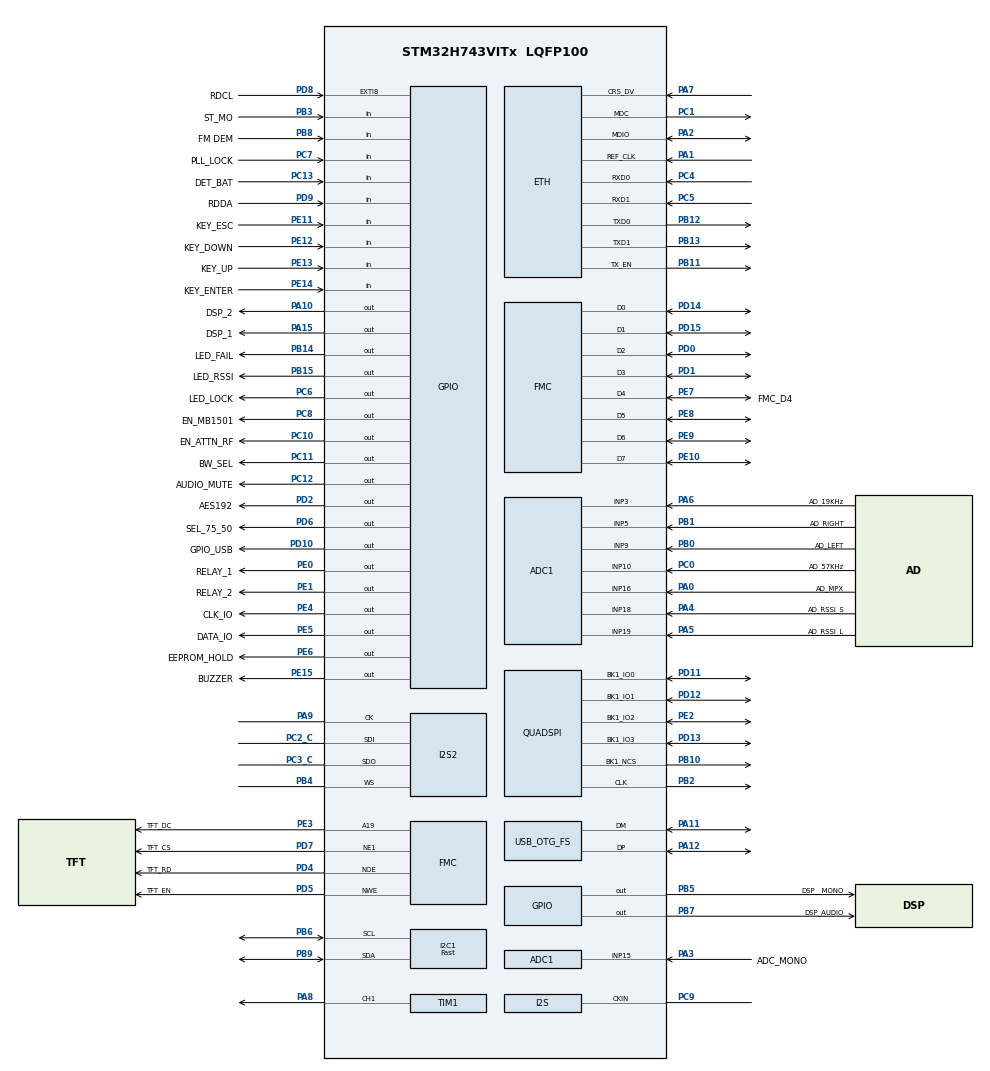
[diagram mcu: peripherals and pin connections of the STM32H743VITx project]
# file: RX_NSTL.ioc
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ADC1.Channel-0\#ChannelRegularConversion=ADC_CHANNEL_16
ADC1.Channel-1\#ChannelRegularConversion=ADC_CHANNEL_15
ADC1.Channel-2\#ChannelRegularConversion=ADC_CHANNEL_18
ADC1.Channel-3\#ChannelRegularConversion=ADC_CHANNEL_19
ADC1.Channel-5\#ChannelRegularConversion=ADC_CHANNEL_3
ADC1.Channel-6\#ChannelRegularConversion=ADC_CHANNEL_9
ADC1.Channel-7\#ChannelRegularConversion=ADC_CHANNEL_5
ADC1.Channel-8\#ChannelRegularConversion=ADC_CHANNEL_10
ADC1.ClockPrescaler=ADC_CLOCK_ASYNC_DIV4
ADC1.ContinuousConvMode=ENABLE
ADC1.ConversionDataManagement=ADC_CONVERSIONDATA_DMA_CIRCULAR
ADC1.NbrOfConversion=8
ADC1.NbrOfConversionFlag=1
ADC1.OffsetNumber-0\#ChannelRegularConversion=ADC_OFFSET_NONE
ADC1.OffsetNumber-1\#ChannelRegularConversion=ADC_OFFSET_NONE
ADC1.OffsetNumber-2\#ChannelRegularConversion=ADC_OFFSET_NONE
ADC1.OffsetNumber-3\#ChannelRegularConversion=ADC_OFFSET_NONE
ADC1.OffsetNumber-5\#ChannelRegularConversion=ADC_OFFSET_NONE
ADC1.OffsetNumber-6\#ChannelRegularConversion=ADC_OFFSET_NONE
ADC1.OffsetNumber-7\#ChannelRegularConversion=ADC_OFFSET_NONE
ADC1.OffsetNumber-8\#ChannelRegularConversion=ADC_OFFSET_NONE
ADC1.OffsetSignedSaturation-0\#ChannelRegularConversion=DISABLE
ADC1.OffsetSignedSaturation-1\#ChannelRegularConversion=DISABLE
ADC1.OffsetSignedSaturation-2\#ChannelRegularConversion=DISABLE
ADC1.OffsetSignedSaturation-3\#ChannelRegularConversion=DISABLE
ADC1.OffsetSignedSaturation-5\#ChannelRegularConversion=DISABLE
ADC1.OffsetSignedSaturation-6\#ChannelRegularConversion=DISABLE
ADC1.OffsetSignedSaturation-7\#ChannelRegularConversion=DISABLE
ADC1.OffsetSignedSaturation-8\#ChannelRegularConversion=DISABLE
ADC1.Overrun=ADC_OVR_DATA_OVERWRITTEN
ADC1.Rank-0\#ChannelRegularConversion=1
ADC1.Rank-1\#ChannelRegularConversion=2
ADC1.Rank-2\#ChannelRegularConversion=3
ADC1.Rank-3\#ChannelRegularConversion=4
ADC1.Rank-5\#ChannelRegularConversion=5
ADC1.Rank-6\#ChannelRegularConversion=6
ADC1.Rank-7\#ChannelRegularConversion=7
ADC1.Rank-8\#ChannelRegularConversion=8
ADC1.SamplingTime-0\#ChannelRegularConversion=ADC_SAMPLETIME_810CYCLES_5
ADC1.SamplingTime-1\#ChannelRegularConversion=ADC_SAMPLETIME_810CYCLES_5
ADC1.SamplingTime-2\#ChannelRegularConversion=ADC_SAMPLETIME_810CYCLES_5
ADC1.SamplingTime-3\#ChannelRegularConversion=ADC_SAMPLETIME_810CYCLES_5
ADC1.SamplingTime-5\#ChannelRegularConversion=ADC_SAMPLETIME_810CYCLES_5
ADC1.SamplingTime-6\#ChannelRegularConversion=ADC_SAMPLETIME_810CYCLES_5
ADC1.SamplingTime-7\#ChannelRegularConversion=ADC_SAMPLETIME_810CYCLES_5
ADC1.SamplingTime-8\#ChannelRegularConversion=ADC_SAMPLETIME_810CYCLES_5
ADC1.master=1
ADC3.Channel-0\#ChannelRegularConversion=ADC_CHANNEL_TEMPSENSOR
ADC3.Channel-1\#ChannelRegularConversion=ADC_CHANNEL_VBAT
ADC3.ClockPrescaler=ADC_CLOCK_ASYNC_DIV4
ADC3.ContinuousConvMode=ENABLE
ADC3.ConversionDataManagement=ADC_CONVERSIONDATA_DMA_CIRCULAR
ADC3.NbrOfConversion=2
ADC3.NbrOfConversionFlag=1
ADC3.OffsetNumber-0\#ChannelRegularConversion=ADC_OFFSET_NONE
ADC3.OffsetNumber-1\#ChannelRegularConversion=ADC_OFFSET_NONE
ADC3.OffsetSignedSaturation-0\#ChannelRegularConversion=DISABLE
ADC3.OffsetSignedSaturation-1\#ChannelRegularConversion=DISABLE
ADC3.Overrun=ADC_OVR_DATA_OVERWRITTEN
ADC3.Rank-0\#ChannelRegularConversion=1
ADC3.Rank-1\#ChannelRegularConversion=2
ADC3.SamplingTime-0\#ChannelRegularConversion=ADC_SAMPLETIME_387CYCLES_5
ADC3.SamplingTime-1\#ChannelRegularConversion=ADC_SAMPLETIME_387CYCLES_5
Bdma.ADC3.0.Direction=DMA_PERIPH_TO_MEMORY
Bdma.ADC3.0.EventEnable=DISABLE
Bdma.ADC3.0.Instance=BDMA_Channel0
Bdma.ADC3.0.MemDataAlignment=DMA_MDATAALIGN_HALFWORD
Bdma.ADC3.0.MemInc=DMA_MINC_ENABLE
Bdma.ADC3.0.Mode=DMA_CIRCULAR
Bdma.ADC3.0.PeriphDataAlignment=DMA_PDATAALIGN_HALFWORD
Bdma.ADC3.0.PeriphInc=DMA_PINC_DISABLE
Bdma.ADC3.0.Polarity=HAL_DMAMUX_REQ_GEN_RISING
Bdma.ADC3.0.Priority=DMA_PRIORITY_LOW
Bdma.ADC3.0.RequestNumber=1
Bdma.ADC3.0.SignalID=NONE
Bdma.ADC3.0.SyncEnable=DISABLE
Bdma.ADC3.0.SyncPolarity=HAL_DMAMUX_SYNC_NO_EVENT
Bdma.ADC3.0.SyncRequestNumber=1
Bdma.ADC3.0.SyncSignalID=NONE
Bdma.Request0=ADC3
Bdma.RequestsNb=1
CORTEX_M7.AccessPermission-Cortex_Memory_Protection_Unit_Region0_Settings=MPU_REGION_FULL_ACCESS
CORTEX_M7.AccessPermission-Cortex_Memory_Protection_Unit_Region1_Settings=MPU_REGION_FULL_ACCESS
CORTEX_M7.AccessPermission-Cortex_Memory_Protection_Unit_Region2_Settings=MPU_REGION_FULL_ACCESS
CORTEX_M7.AccessPermission-Cortex_Memory_Protection_Unit_Region3_Settings=MPU_REGION_FULL_ACCESS
CORTEX_M7.AccessPermission_S-Cortex_Memory_Protection_Unit_Region1_Settings_S=MPU_REGION_FULL_ACCESS
CORTEX_M7.AccessPermission_S-Cortex_Memory_Protection_Unit_Region2_Settings_S=MPU_REGION_FULL_ACCESS
CORTEX_M7.AccessPermission_S-Cortex_Memory_Protection_Unit_Region3_Settings_S=MPU_REGION_FULL_ACCESS
CORTEX_M7.AccessPermission_S-Cortex_Memory_Protection_Unit_Region4_Settings_S=MPU_REGION_FULL_ACCESS
CORTEX_M7.BaseAddress-Cortex_Memory_Protection_Unit_Region0_Settings=0x30040000
CORTEX_M7.BaseAddress-Cortex_Memory_Protection_Unit_Region1_Settings=0x30040000
CORTEX_M7.BaseAddress-Cortex_Memory_Protection_Unit_Region2_Settings=0x60000000
CORTEX_M7.BaseAddress-Cortex_Memory_Protection_Unit_Region3_Settings=0x60010000
CORTEX_M7.BaseAddress_S-Cortex_Memory_Protection_Unit_Region1_Settings_S=0x30020000
CORTEX_M7.BaseAddress_S-Cortex_Memory_Protection_Unit_Region2_Settings_S=0x30040000
CORTEX_M7.BaseAddress_S-Cortex_Memory_Protection_Unit_Region3_Settings_S=0x60000000
CORTEX_M7.BaseAddress_S-Cortex_Memory_Protection_Unit_Region4_Settings_S=0x60080000
CORTEX_M7.CPU_DCache=Enabled
CORTEX_M7.CPU_ICache=Enabled
CORTEX_M7.DisableExec-Cortex_Memory_Protection_Unit_Region0_Settings=MPU_INSTRUCTION_ACCESS_DISABLE
CORTEX_M7.DisableExec-Cortex_Memory_Protection_Unit_Region1_Settings=MPU_INSTRUCTION_ACCESS_DISABLE
CORTEX_M7.DisableExec-Cortex_Memory_Protection_Unit_Region2_Settings=MPU_INSTRUCTION_ACCESS_DISABLE
CORTEX_M7.DisableExec-Cortex_Memory_Protection_Unit_Region3_Settings=MPU_INSTRUCTION_ACCESS_DISABLE
CORTEX_M7.DisableExec_S-Cortex_Memory_Protection_Unit_Region1_Settings_S=MPU_INSTRUCTION_ACCESS_DISABLE
CORTEX_M7.DisableExec_S-Cortex_Memory_Protection_Unit_Region2_Settings_S=MPU_INSTRUCTION_ACCESS_DISABLE
CORTEX_M7.DisableExec_S-Cortex_Memory_Protection_Unit_Region3_Settings_S=MPU_INSTRUCTION_ACCESS_DISABLE
CORTEX_M7.DisableExec_S-Cortex_Memory_Protection_Unit_Region4_Settings_S=MPU_INSTRUCTION_ACCESS_DISABLE
CORTEX_M7.Enable-Cortex_Memory_Protection_Unit_Region0_Settings=MPU_REGION_ENABLE
CORTEX_M7.Enable-Cortex_Memory_Protection_Unit_Region1_Settings=MPU_REGION_ENABLE
CORTEX_M7.Enable-Cortex_Memory_Protection_Unit_Region2_Settings=MPU_REGION_ENABLE
CORTEX_M7.Enable-Cortex_Memory_Protection_Unit_Region3_Settings=MPU_REGION_ENABLE
CORTEX_M7.Enable_S-Cortex_Memory_Protection_Unit_Region1_Settings_S=MPU_REGION_ENABLE
CORTEX_M7.Enable_S-Cortex_Memory_Protection_Unit_Region2_Settings_S=MPU_REGION_ENABLE
CORTEX_M7.Enable_S-Cortex_Memory_Protection_Unit_Region3_Settings_S=MPU_REGION_ENABLE
CORTEX_M7.Enable_S-Cortex_Memory_Protection_Unit_Region4_Settings_S=MPU_REGION_ENABLE
CORTEX_M7.IsBufferable-Cortex_Memory_Protection_Unit_Region1_Settings=MPU_ACCESS_BUFFERABLE
CORTEX_M7.IsBufferable_S-Cortex_Memory_Protection_Unit_Region2_Settings_S=MPU_ACCESS_BUFFERABLE
CORTEX_M7.IsBufferable_S-Cortex_Memory_Protection_Unit_Region3_Settings_S=MPU_ACCESS_NOT_BUFFERABLE
CORTEX_M7.IsBufferable_S-Cortex_Memory_Protection_Unit_Region4_Settings_S=MPU_ACCESS_NOT_BUFFERABLE
CORTEX_M7.IsShareable-Cortex_Memory_Protection_Unit_Region1_Settings=MPU_ACCESS_SHAREABLE
CORTEX_M7.IsShareable_S-Cortex_Memory_Protection_Unit_Region2_Settings_S=MPU_ACCESS_SHAREABLE
CORTEX_M7.IsShareable_S-Cortex_Memory_Protection_Unit_Region3_Settings_S=MPU_ACCESS_NOT_SHAREABLE
CORTEX_M7.IsShareable_S-Cortex_Memory_Protection_Unit_Region4_Settings_S=MPU_ACCESS_NOT_SHAREABLE
CORTEX_M7.MPU_Control=MPU_PRIVILEGED_DEFAULT
CORTEX_M7.Size-Cortex_Memory_Protection_Unit_Region0_Settings=MPU_REGION_SIZE_32KB
CORTEX_M7.Size-Cortex_Memory_Protection_Unit_Region1_Settings=MPU_REGION_SIZE_256B
CORTEX_M7.Size-Cortex_Memory_Protection_Unit_Region2_Settings=MPU_REGION_SIZE_4KB
CORTEX_M7.Size-Cortex_Memory_Protection_Unit_Region3_Settings=MPU_REGION_SIZE_4KB
CORTEX_M7.Size_S-Cortex_Memory_Protection_Unit_Region1_Settings_S=MPU_REGION_SIZE_128KB
CORTEX_M7.Size_S-Cortex_Memory_Protection_Unit_Region2_Settings_S=MPU_REGION_SIZE_512B
CORTEX_M7.Size_S-Cortex_Memory_Protection_Unit_Region3_Settings_S=MPU_REGION_SIZE_4KB
CORTEX_M7.Size_S-Cortex_Memory_Protection_Unit_Region4_Settings_S=MPU_REGION_SIZE_4KB
CORTEX_M7.TypeExtField-Cortex_Memory_Protection_Unit_Region0_Settings=MPU_TEX_LEVEL1
CORTEX_M7.TypeExtField_S-Cortex_Memory_Protection_Unit_Region1_Settings_S=MPU_TEX_LEVEL1
CORTEX_M7.default_mode_Activation=1
DMA2D.Mode=DMA2D_M2M_PFC
Dma.ADC1.0.Direction=DMA_PERIPH_TO_MEMORY
Dma.ADC1.0.EventEnable=DISABLE
Dma.ADC1.0.FIFOMode=DMA_FIFOMODE_DISABLE
Dma.ADC1.0.Instance=DMA1_Stream0
Dma.ADC1.0.MemDataAlignment=DMA_MDATAALIGN_HALFWORD
Dma.ADC1.0.MemInc=DMA_MINC_ENABLE
Dma.ADC1.0.Mode=DMA_CIRCULAR
Dma.ADC1.0.PeriphDataAlignment=DMA_PDATAALIGN_HALFWORD
Dma.ADC1.0.PeriphInc=DMA_PINC_DISABLE
Dma.ADC1.0.Polarity=HAL_DMAMUX_REQ_GEN_RISING
Dma.ADC1.0.Priority=DMA_PRIORITY_HIGH
Dma.ADC1.0.RequestNumber=1
Dma.ADC1.0.SignalID=NONE
Dma.ADC1.0.SyncEnable=DISABLE
Dma.ADC1.0.SyncPolarity=HAL_DMAMUX_SYNC_NO_EVENT
Dma.ADC1.0.SyncRequestNumber=1
Dma.ADC1.0.SyncSignalID=NONE
Dma.MEMTOMEM.1.Direction=DMA_MEMORY_TO_MEMORY
Dma.MEMTOMEM.1.EventEnable=DISABLE
Dma.MEMTOMEM.1.FIFOMode=DMA_FIFOMODE_ENABLE
Dma.MEMTOMEM.1.FIFOThreshold=DMA_FIFO_THRESHOLD_FULL
Dma.MEMTOMEM.1.Instance=DMA1_Stream1
Dma.MEMTOMEM.1.MemBurst=DMA_MBURST_SINGLE
Dma.MEMTOMEM.1.MemDataAlignment=DMA_MDATAALIGN_BYTE
Dma.MEMTOMEM.1.MemInc=DMA_MINC_DISABLE
Dma.MEMTOMEM.1.Mode=DMA_NORMAL
Dma.MEMTOMEM.1.PeriphBurst=DMA_PBURST_SINGLE
Dma.MEMTOMEM.1.PeriphDataAlignment=DMA_PDATAALIGN_BYTE
Dma.MEMTOMEM.1.PeriphInc=DMA_PINC_ENABLE
Dma.MEMTOMEM.1.Polarity=HAL_DMAMUX_REQ_GEN_RISING
Dma.MEMTOMEM.1.Priority=DMA_PRIORITY_LOW
Dma.MEMTOMEM.1.RequestNumber=1
Dma.MEMTOMEM.1.SignalID=NONE
Dma.MEMTOMEM.1.SyncEnable=DISABLE
Dma.MEMTOMEM.1.SyncPolarity=HAL_DMAMUX_SYNC_NO_EVENT
Dma.MEMTOMEM.1.SyncRequestNumber=1
Dma.MEMTOMEM.1.SyncSignalID=NONE
Dma.Request0=ADC1
Dma.Request1=MEMTOMEM
ETH.MACAddr=00\:80\:E1\:00\:00\:02
ETH.MediaInterface=HAL_ETH_RMII_MODE
FATFS._FS_EXFAT=1
FATFS._MAX_SS=4096
FATFS._USE_LFN=2
FMC.AddressSetupTime1=8
FMC.BusTurnAroundDuration1=8
FMC.DataSetupTime1=30
FREERTOS.BinarySemaphores01=BinarySemI2C,Dynamic,NULL,;BinarySemLVGL,Dynamic,NULL,;BinarySemHTTPD,Dynamic,NULL,;BinarySemMQTT,Dynamic,NULL,Available
FREERTOS.Mutexes01=MutexI2C,Dynamic,NULL;MutexLVGL,Dynamic,NULL;MutexHTTPD,Dynamic,NULL
FREERTOS.Queues01=QueueUSART3,16,uint8_t,0,Dynamic,NULL,NULL;QueueUSART6,16,uint8_t,0,Dynamic,NULL,NULL;QueueBuzzer,1,uint32_t,0,Dynamic,NULL,NULL;QueueHttp,1,uint32_t,0,Dynamic,NULL,NULL;QueueMqtt,50,10,1,Dynamic,NULL,NULL
FREERTOS.Tasks01=TaskMain,24,1024,StartTaskMain,Default,NULL,Dynamic,NULL,NULL;TaskGUI,8,4096,StartTaskGUI,Default,NULL,Dynamic,NULL,NULL;TaskNTP,8,1024,StartTaskNTP,Default,NULL,Dynamic,NULL,NULL
FREERTOS.configCHECK_FOR_STACK_OVERFLOW=2
FREERTOS.configENABLE_FPU=0
FREERTOS.configGENERATE_RUN_TIME_STATS=1
FREERTOS.configMINIMAL_STACK_SIZE=512
FREERTOS.configRECORD_STACK_HIGH_ADDRESS=1
FREERTOS.configTOTAL_HEAP_SIZE=73728
FREERTOS.configUSE_NEWLIB_REENTRANT=1
FREERTOS.configUSE_STATS_FORMATTING_FUNCTIONS=1
I2C1.I2C_Speed_Mode=I2C_Fast
I2C1.Timing=0x00B03FDB
I2S2.AudioFreq=I2S_AUDIOFREQ_192K
I2S2.DataFormat=I2S_DATAFORMAT_24B
I2S2.ErrorAudioFreq=0.0 %
I2S2.Instance=SPI$Index
I2S2.RealAudioFreq=192.0 KHz
IWDG1.Prescaler=IWDG_PRESCALER_256
IWDG1.Reload=2500
IWDG1.Window=2500
LWIP.BSP.number=1
LWIP.CMSIS_VERSION-Enabled=1
LWIP.DEFAULT_THREAD_STACKSIZE=4096
LWIP.ETHARP_SUPPORT_VLAN=1
LWIP.GATEWAY_ADDRESS=010.055.001.001
LWIP.HTTPD_USE_CUSTOM_FSDATA=1
LWIP.IP_ADDRESS=010.055.001.011
LWIP.LINK_STATS=1
LWIP.LWIP_ALTCP=1
LWIP.LWIP_ALTCP_TLS=1
LWIP.LWIP_BROADCAST_PING=1
LWIP.LWIP_DHCP=0
LWIP.LWIP_DNS=1
LWIP.LWIP_HTTPD=1
LWIP.LWIP_HTTPD_CGI=1
LWIP.LWIP_HTTPD_DYNAMIC_HEADERS=1
LWIP.LWIP_HTTPD_FS_ASYNC_READ=1
LWIP.LWIP_HTTPD_MAX_REQ_LENGTH=2048
LWIP.LWIP_HTTPD_MAX_TAG_NAME_LEN=16
LWIP.LWIP_HTTPD_REQ_BUFSIZE=2048
LWIP.LWIP_HTTPD_SSI=1
LWIP.LWIP_HTTPD_SUPPORT_POST=1
LWIP.LWIP_MULTICAST_PING=1
LWIP.LWIP_NETCONN_FULLDUPLEX=1
LWIP.LWIP_NETIF_STATUS_CALLBACK=1
LWIP.LWIP_RAM_HEAP_POINTER=0x30020000
LWIP.LWIP_SNMP=1
LWIP.LWIP_SNTP=1
LWIP.LWIP_SO_RCVBUF=1
LWIP.LWIP_SO_RCVTIMEO=1
LWIP.LWIP_TCPIP_TIMEOUT=1
LWIP.LWIP_TCP_KEEPALIVE=1
LWIP.MEMP_NUM_FRAG_PBUF=15
LWIP.MEMP_NUM_NETBUF=10
LWIP.MEMP_NUM_NETCONN=10
LWIP.MEMP_NUM_REASSDATA=5
LWIP.MEMP_NUM_TCP_PCB=10
LWIP.MEMP_NUM_TCP_PCB_LISTEN=10
LWIP.MEMP_NUM_TCP_SEG=32
LWIP.MEM_SIZE=131048
LWIP.NETMASK_ADDRESS=255.255.255.000
LWIP.SLIPIF_THREAD_STACKSIZE=3072
LWIP.SNMP_USE_NETCONN=1
LWIP.SNMP_USE_RAW=0
LWIP.TCPIP_THREAD_PRIO=40
LWIP.TCPIP_THREAD_STACKSIZE=3072
LWIP.TCP_DEFAULT_LISTEN_BACKLOG=4
LWIP.TCP_MSS=1460
LWIP.TCP_SND_BUF=5840
LWIP.TCP_SND_QUEUELEN=16
LWIP.TCP_WND=5840
LWIP.Version=v2.1.2_Cube
LWIP0.BSP.STBoard=false
LWIP0.BSP.api=BSP_COMPONENT_DRIVER
LWIP0.BSP.component=LAN8742
LWIP0.BSP.instance=LAN8742
LWIP0.BSP.name=Driver_PHY
LWIP0.BSP.semaphore=S_LAN8742
LWIP0.BSP.solution=LAN8742
Mcu.Family=STM32H7
Mcu.Name=STM32H743VITx
Mcu.Package=LQFP100
Mdma.MDMA_Channel0.DMA1_Stream1_TC.0.BlockCount=0
Mdma.MDMA_Channel0.DMA1_Stream1_TC.0.BlockDataLength=0
Mdma.MDMA_Channel0.DMA1_Stream1_TC.0.BufferTransferLength=1
Mdma.MDMA_Channel0.DMA1_Stream1_TC.0.CircularMode=MDMA_LINEAR_LIST
Mdma.MDMA_Channel0.DMA1_Stream1_TC.0.DataAlignment=MDMA_DATAALIGN_PACKENABLE
Mdma.MDMA_Channel0.DMA1_Stream1_TC.0.DestBlockAddressOffset=0
Mdma.MDMA_Channel0.DMA1_Stream1_TC.0.DestBurst=MDMA_DEST_BURST_SINGLE
Mdma.MDMA_Channel0.DMA1_Stream1_TC.0.DestDataSize=MDMA_DEST_DATASIZE_BYTE
Mdma.MDMA_Channel0.DMA1_Stream1_TC.0.DestinationInc=MDMA_DEST_INC_DISABLE
Mdma.MDMA_Channel0.DMA1_Stream1_TC.0.DstAddress=0
Mdma.MDMA_Channel0.DMA1_Stream1_TC.0.Endianness=MDMA_LITTLE_ENDIANNESS_PRESERVE
Mdma.MDMA_Channel0.DMA1_Stream1_TC.0.Instance=MDMA_Channel0
Mdma.MDMA_Channel0.DMA1_Stream1_TC.0.MaskAddress=0
Mdma.MDMA_Channel0.DMA1_Stream1_TC.0.MaskData=0
Mdma.MDMA_Channel0.DMA1_Stream1_TC.0.Priority=MDMA_PRIORITY_MEDIUM
Mdma.MDMA_Channel0.DMA1_Stream1_TC.0.Rank=First
Mdma.MDMA_Channel0.DMA1_Stream1_TC.0.SourceBlockAddressOffset=0
Mdma.MDMA_Channel0.DMA1_Stream1_TC.0.SourceBurst=MDMA_SOURCE_BURST_SINGLE
Mdma.MDMA_Channel0.DMA1_Stream1_TC.0.SourceDataSize=MDMA_SRC_DATASIZE_BYTE
Mdma.MDMA_Channel0.DMA1_Stream1_TC.0.SourceInc=MDMA_SRC_INC_BYTE
Mdma.MDMA_Channel0.DMA1_Stream1_TC.0.SrcAddress=0
Mdma.MDMA_Channel0.DMA1_Stream1_TC.0.TransferTriggerMode=MDMA_BUFFER_TRANSFER
Mdma.MDMA_Channel0.Request0=DMA1_Stream1_TC
Mdma.MDMA_Channel0.RequestsNb=1
Mdma.RequestSet0=MDMA_Channel0
Mdma.RequestSetsNb=1
NVIC.BDMA_Channel0_IRQn=true\:5\:0\:false\:false\:true\:true\:false\:true\:true
NVIC.DMA1_Stream0_IRQn=true\:5\:0\:false\:false\:true\:true\:false\:true\:true
NVIC.DMA1_Stream1_IRQn=true\:5\:0\:true\:false\:true\:false\:true\:true\:true
NVIC.DMA2D_IRQn=true\:5\:0\:false\:false\:true\:true\:true\:true\:true
NVIC.ETH_IRQn=true\:5\:0\:false\:false\:true\:true\:true\:true\:true
NVIC.MDMA_IRQn=true\:5\:0\:false\:false\:true\:true\:false\:true\:true
NVIC.OTG_FS_IRQn=true\:5\:0\:false\:false\:true\:true\:false\:true\:true
NVIC.PriorityGroup=NVIC_PRIORITYGROUP_4
NVIC.QUADSPI_IRQn=true\:5\:0\:false\:false\:true\:true\:true\:true\:true
NVIC.TIM6_DAC_IRQn=true\:15\:0\:false\:false\:true\:false\:false\:true\:true
NVIC.TIM8_BRK_TIM12_IRQn=true\:5\:0\:false\:false\:true\:true\:true\:true\:true
NVIC.TimeBase=TIM6_DAC_IRQn
NVIC.TimeBaseIP=TIM6
PA0.GPIO_Label=AD_MPX
PA0.Mode=IN16-Single-Ended
PA0.Signal=ADC1_INP16
PA1.GPIO_Speed=GPIO_SPEED_FREQ_VERY_HIGH
PA1.Mode=RMII
PA1.Signal=ETH_REF_CLK
PA10.GPIO_Label=DSP_2
PA10.Signal=GPIO_Output
PA11.Mode=Host_Only
PA11.Signal=USB_OTG_FS_DM
PA12.Mode=Host_Only
PA12.Signal=USB_OTG_FS_DP
PA13\ (JTMS/SWDIO).Mode=Serial_Wire
PA13\ (JTMS/SWDIO).Signal=DEBUG_JTMS-SWDIO
PA14\ (JTCK/SWCLK).Mode=Serial_Wire
PA14\ (JTCK/SWCLK).Signal=DEBUG_JTCK-SWCLK
PA15\ (JTDI).GPIO_Label=DSP_1
PA15\ (JTDI).Signal=GPIO_Output
PA2.GPIO_Speed=GPIO_SPEED_FREQ_VERY_HIGH
PA2.Mode=RMII
PA2.Signal=ETH_MDIO
PA3.GPIO_Label=ADC_MONO
PA3.Signal=ADCx_INP15
PA4.GPIO_Label=AD_RSSI_S
PA4.Signal=ADCx_INP18
PA5.GPIO_Label=AD_RSSI_L
PA5.Signal=ADCx_INP19
PA6.GPIO_Label=AD_19KHz
PA6.Signal=ADCx_INP3
PA7.GPIO_Speed=GPIO_SPEED_FREQ_VERY_HIGH
PA7.Mode=RMII
PA7.Signal=ETH_CRS_DV
PA8.Signal=S_TIM1_CH1
PA9.Mode=Full_Duplex_Master
PA9.Signal=I2S2_CK
PB0.GPIO_Label=AD_LEFT
PB0.Signal=ADCx_INP9
PB1.GPIO_Label=AD_RIGHT
PB1.Signal=ADCx_INP5
PB10.GPIO_Speed=GPIO_SPEED_FREQ_VERY_HIGH
PB10.Mode=Single Bank 1
PB10.Signal=QUADSPI_BK1_NCS
PB11.GPIO_Speed=GPIO_SPEED_FREQ_VERY_HIGH
PB11.Mode=RMII
PB11.Signal=ETH_TX_EN
PB12.GPIO_Speed=GPIO_SPEED_FREQ_VERY_HIGH
PB12.Mode=RMII
PB12.Signal=ETH_TXD0
PB13.GPIO_Speed=GPIO_SPEED_FREQ_VERY_HIGH
PB13.Mode=RMII
PB13.Signal=ETH_TXD1
PB14.GPIO_Label=LED_FAIL
PB14.Signal=GPIO_Output
PB15.GPIO_Label=LED_RSSI
PB15.Signal=GPIO_Output
PB2.GPIO_Speed=GPIO_SPEED_FREQ_VERY_HIGH
PB2.Mode=Single Bank 1
PB2.Signal=QUADSPI_CLK
PB3\ (JTDO/TRACESWO).GPIO_Label=ST_MO
PB3\ (JTDO/TRACESWO).Signal=GPIO_Input
PB4\ (NJTRST).Mode=Full_Duplex_Master
PB4\ (NJTRST).Signal=I2S2_WS
PB5.GPIO_Label=DSP__MONO
PB5.Signal=GPIO_Output
PB6.GPIO_Pu=GPIO_PULLUP
PB6.GPIO_PuPd=GPIO_PULLUP
PB6.Mode=I2C
PB6.Signal=I2C1_SCL
PB7.GPIO_Label=DSP_AUDIO
PB7.Signal=GPIO_Output
PB8.GPIO_Label=FM DEM
PB8.Signal=GPIO_Input
PB9.GPIO_Pu=GPIO_PULLUP
PB9.GPIO_PuPd=GPIO_PULLUP
PB9.Mode=I2C
PB9.Signal=I2C1_SDA
PC0.GPIO_Label=AD_57KHz
PC0.Signal=ADCx_INP10
PC1.Mode=RMII
PC1.Signal=ETH_MDC
PC10.GPIO_Label=EN_ATTN_RF
PC10.PinState=GPIO_PIN_SET
PC10.Signal=GPIO_Output
PC11.GPIO_Label=BW_SEL
PC11.PinState=GPIO_PIN_SET
PC11.Signal=GPIO_Output
PC12.GPIO_Label=AUDIO_MUTE
PC12.PinState=GPIO_PIN_SET
PC12.Signal=GPIO_Output
PC13.GPIO_Label=DET_BAT
PC13.Signal=GPIO_Input
PC14-OSC32_IN\ (OSC32_IN).Mode=LSE-External-Oscillator
PC14-OSC32_IN\ (OSC32_IN).Signal=RCC_OSC32_IN
PC15-OSC32_OUT\ (OSC32_OUT).Mode=LSE-External-Oscillator
PC15-OSC32_OUT\ (OSC32_OUT).Signal=RCC_OSC32_OUT
PC2_C.Mode=Full_Duplex_Master
PC2_C.Signal=I2S2_SDI
PC3_C.Mode=Full_Duplex_Master
PC3_C.Signal=I2S2_SDO
PC4.GPIO_Speed=GPIO_SPEED_FREQ_VERY_HIGH
PC4.Mode=RMII
PC4.Signal=ETH_RXD0
PC5.GPIO_Speed=GPIO_SPEED_FREQ_VERY_HIGH
PC5.Mode=RMII
PC5.Signal=ETH_RXD1
PC6.GPIO_Label=LED_LOCK
PC6.Signal=GPIO_Output
PC7.GPIO_Label=PLL_LOCK
PC7.Signal=GPIO_Input
PC8.GPIO_Label=EN_MB1501
PC8.PinState=GPIO_PIN_SET
PC8.Signal=GPIO_Output
PC9.Mode=Audio_ClockIn
PC9.Signal=I2S_CKIN
PD0.Signal=FMC_D2_DA2
PD1.Signal=FMC_D3_DA3
PD10.GPIO_Label=GPIO_USB
PD10.Signal=GPIO_Output
PD11.Mode=Single Bank 1
PD11.Signal=QUADSPI_BK1_IO0
PD12.GPIO_Speed=GPIO_SPEED_FREQ_VERY_HIGH
PD12.Mode=Single Bank 1
PD12.Signal=QUADSPI_BK1_IO1
PD13.GPIO_Speed=GPIO_SPEED_FREQ_VERY_HIGH
PD13.Mode=Single Bank 1
PD13.Signal=QUADSPI_BK1_IO3
PD14.Signal=FMC_D0_DA0
PD15.Signal=FMC_D1_DA1
PD2.GPIO_Label=AES192
PD2.Signal=GPIO_Output
PD4.GPIO_Label=TFT_RD
PD4.Signal=FMC_NOE
PD5.GPIO_Label=TFT_EN
PD5.Signal=FMC_NWE
PD6.GPIO_Label=SEL_75_50
PD6.PinState=GPIO_PIN_SET
PD6.Signal=GPIO_Output
PD7.GPIO_Label=TFT_CS
PD7.Mode=NorPsramChipSelect1_1
PD7.Signal=FMC_NE1
PD8.GPIO_Label=RDCL
PD8.GPIO_PuPd=GPIO_PULLUP
PD8.Signal=GPXTI8
PD9.GPIO_Label=RDDA
PD9.GPIO_PuPd=GPIO_PULLUP
PD9.Signal=GPIO_Input
PE0.GPIO_Label=RELAY_1
PE0.Signal=GPIO_Output
PE1.GPIO_Label=RELAY_2
PE1.Signal=GPIO_Output
PE10.Signal=FMC_D7_DA7
PE11.GPIO_Label=KEY_ESC
PE11.Signal=GPIO_Input
PE12.GPIO_Label=KEY_DOWN
PE12.Signal=GPIO_Input
PE13.GPIO_Label=KEY_UP
PE13.Signal=GPIO_Input
PE14.GPIO_Label=KEY_ENTER
PE14.Signal=GPIO_Input
PE15.GPIO_Label=BUZZER
PE15.Signal=GPIO_Output
PE2.GPIO_Speed=GPIO_SPEED_FREQ_VERY_HIGH
PE2.Mode=Single Bank 1
PE2.Signal=QUADSPI_BK1_IO2
PE3.GPIO_Label=TFT_DC
PE3.Signal=FMC_A19
PE4.GPIO_Label=CLK_IO
PE4.Signal=GPIO_Output
PE5.GPIO_Label=DATA_IO
PE5.Signal=GPIO_Output
PE6.GPIO_Label=EEPROM_HOLD
PE6.PinState=GPIO_PIN_SET
PE6.Signal=GPIO_Output
PE7.GPIO_Label=FMC_D4
PE7.Signal=FMC_D4_DA4
PE8.Signal=FMC_D5_DA5
PE9.Signal=FMC_D6_DA6
PH0-OSC_IN\ (PH0).Mode=HSE-External-Oscillator
PH0-OSC_IN\ (PH0).Signal=RCC_OSC_IN
PH1-OSC_OUT\ (PH1).Mode=HSE-External-Oscillator
PH1-OSC_OUT\ (PH1).Signal=RCC_OSC_OUT
ProjectManager.HeapSize=0x10000
ProjectManager.StackSize=0x1000
ProjectManager.TargetToolchain=STM32CubeIDE
QUADSPI.ChipSelectHighTime=QSPI_CS_HIGH_TIME_8_CYCLE
QUADSPI.ClockPrescaler=2
QUADSPI.FifoThreshold=4
QUADSPI.FlashSize=25
QUADSPI.SampleShifting=QSPI_SAMPLE_SHIFTING_HALFCYCLE
RCC.ADCCLockSelection=RCC_ADCCLKSOURCE_PLL3
RCC.ADCFreq_Value=96000000
RCC.APB1Freq_Value=120000000
RCC.APB2Freq_Value=120000000
RCC.APB3Freq_Value=120000000
RCC.APB4Freq_Value=120000000
RCC.CortexFreq_Value=480000000
RCC.D1PPRE=RCC_APB3_DIV2
RCC.D2PPRE1=RCC_APB1_DIV2
RCC.D2PPRE2=RCC_APB2_DIV2
RCC.D3PPRE=RCC_APB4_DIV2
RCC.DIVM1=4
RCC.DIVM2=4
RCC.DIVM3=4
RCC.DIVN1=480
RCC.DIVN2=480
RCC.DIVN3=480
RCC.DIVQ1=8
RCC.DIVQ3=20
RCC.DIVR1=8
RCC.DIVR2=8
RCC.DIVR3=10
RCC.EXTERNAL_CLOCK_VALUE=24576000
RCC.FMCCLockSelection=RCC_FMCCLKSOURCE_PLL2
RCC.HCLKFreq_Value=240000000
RCC.HPRE=RCC_HCLK_DIV2
RCC.HSE_VALUE=8000000
RCC.LSE_Drive_Capability=RCC_LSEDRIVE_HIGH
RCC.PLLSourceVirtual=RCC_PLLSOURCE_HSE
RCC.PWR_Regulator_Voltage_Scale=PWR_REGULATOR_VOLTAGE_SCALE0
RCC.QSPICLockSelection=RCC_QSPICLKSOURCE_PLL2
RCC.RNGCLockSelection=RCC_RNGCLKSOURCE_PLL
RCC.RTCClockSelection=RCC_RTCCLKSOURCE_LSE
RCC.SAI1CLockSelection=RCC_SAI1CLKSOURCE_PIN
RCC.SPI123CLockSelection=RCC_SPI123CLKSOURCE_PIN
RCC.SYSCLKFreq_VALUE=480000000
RCC.SYSCLKSource=RCC_SYSCLKSOURCE_PLLCLK
RCC.USBCLockSelection=RCC_USBCLKSOURCE_PLL3
RCC.USBFreq_Value=48000000
RTC.Format=RTC_FORMAT_BIN
SH.ADCx_INP10.0=ADC1_INP10,IN10-Single-Ended
SH.ADCx_INP15.0=ADC1_INP15,IN15-Single-Ended
SH.ADCx_INP18.0=ADC1_INP18,IN18-Single-Ended
SH.ADCx_INP19.0=ADC1_INP19,IN19-Single-Ended
SH.ADCx_INP3.0=ADC1_INP3,IN3-Single-Ended
SH.ADCx_INP5.0=ADC1_INP5,IN5-Single-Ended
SH.ADCx_INP9.0=ADC1_INP9,IN9-Single-Ended
SH.FMC_A19.0=FMC_A19,A19_1
SH.FMC_D0_DA0.0=FMC_D0,8b-d1
SH.FMC_D1_DA1.0=FMC_D1,8b-d1
SH.FMC_D2_DA2.0=FMC_D2,8b-d1
SH.FMC_D3_DA3.0=FMC_D3,8b-d1
SH.FMC_D4_DA4.0=FMC_D4,8b-d1
SH.FMC_D5_DA5.0=FMC_D5,8b-d1
SH.FMC_D6_DA6.0=FMC_D6,8b-d1
SH.FMC_D7_DA7.0=FMC_D7,8b-d1
SH.FMC_NOE.0=FMC_NOE,Lcd1
SH.FMC_NWE.0=FMC_NWE,Lcd1
SH.S_TIM1_CH1.0=TIM1_CH1,PWM Generation1 CH1
TIM1.AutoReloadPreload=TIM_AUTORELOAD_PRELOAD_DISABLE
TIM1.Channel-PWM\ Generation1\ CH1=TIM_CHANNEL_1
TIM1.Period=4095
TIM1.Prescaler=1
TIM12.AutoReloadPreload=TIM_AUTORELOAD_PRELOAD_ENABLE
TIM12.Period=1000
TIM12.Prescaler=1
USB_HOST.BSP.number=1
USB_HOST.USBH_HandleTypeDef-MSC_FS=hUsbHostFS
USB_HOST.VirtualModeFS=Msc
USB_HOST0.BSP.STBoard=false
USB_HOST0.BSP.api=Unknown
USB_HOST0.BSP.condition=SW_VBUS_DRIVE_MSC_FS \= false
USB_HOST0.BSP.instance=PD10
USB_HOST0.BSP.ip=GPIO
USB_HOST0.BSP.mode=Output
USB_HOST0.BSP.name=Drive_VBUS_FS
USB_HOST0.BSP.solution=PD10
USB_OTG_FS.VirtualMode=Host_Only
USB_OTG_FS.phy_itface=HCD_PHY_EMBEDDED
VP_ADC3_TempSens_Input.Mode=IN-TempSens
VP_ADC3_Vbat_Input.Mode=IN-Vbat
VP_CRC_VS_CRC.Mode=CRC_Activate
VP_DMA2D_VS_DMA2D.Mode=DMA2D_Activate
VP_FATFS_VS_Generic.Mode=User_defined
VP_FATFS_VS_USB.Mode=USB
VP_FREERTOS_VS_CMSIS_V2.Mode=CMSIS_V2
VP_IWDG1_VS_IWDG.Mode=IWDG_Activate
VP_LWIP_VS_Enabled.Mode=Enabled
VP_MBEDTLS_VS_MBEDTLS.Mode=Enabled
VP_MEMORYMAP_VS_MEMORYMAP.Mode=CurAppReg
VP_RNG_VS_RNG.Mode=RNG_Activate
VP_RTC_VS_RTC_Activate.Mode=RTC_Enabled
VP_RTC_VS_RTC_Calendar.Mode=RTC_Calendar
VP_SYS_VS_tim6.Mode=TIM6
VP_TIM12_VS_ClockSourceINT.Mode=Internal
VP_TIM1_VS_ClockSourceINT.Mode=Internal
VP_USB_HOST_VS_USB_HOST_MSC_FS.Mode=MSC_FS
board=custom

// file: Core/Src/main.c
/* USER CODE BEGIN Header */
/**
  ******************************************************************************
  * @file           : main.c
  * @brief          : Main program body
  ******************************************************************************
  * @attention
  *
  * Copyright (c) 2025 STMicroelectronics.
  * All rights reserved.
  *
  * This software is licensed under terms that can be found in the LICENSE file
  * in the root directory of this software component.
  * If no LICENSE file comes with this software, it is provided AS-IS.
  *
  ******************************************************************************
  */
/* USER CODE END Header */
#include "main.h"
#include "cmsis_os.h"
#include "adc.h"
#include "bdma.h"
#include "crc.h"
#include "dma.h"
#include "dma2d.h"
#include "fatfs.h"
#include "i2c.h"
#include "i2s.h"
#include "iwdg.h"
#include "mdma.h"
#include "quadspi.h"
#include "rng.h"
#include "rtc.h"
#include "tim.h"
#include "usb_host.h"
#include "gpio.h"
#include "fmc.h"
#include "mbedtls.h"

/* USER CODE BEGIN Includes */
#include <sys/time.h>
#include "../Sinteck/display/Drv_SSD1963.h"
#include "../Sinteck/src/keys.h"
#include "../Sinteck/src/buzzer.h"
/* USER CODE END Includes */

/* USER CODE BEGIN PTD */
reset_cause_t reset_cause_get(void);
void Read_Remote(void);
void MCU_TemperatureCalculate(uint32_t ts_data);
void MCU_Temperature(void);
/* USER CODE END PTD */

/* USER CODE BEGIN PV */
#define DEBOUNCE_REMOTE		500
extern volatile unsigned long ulHighFrequencyTimerTicks;

extern volatile unsigned long MilliTimer;
uint32_t timer_lvgl = 0;
uint32_t timer_key = 0;
GPIO_PinState BatteryInput;
GPIO_PinState StereoMonoInput;
GPIO_PinState FMDemInput;

uint32_t deb_battery_l = 0;
uint32_t deb_battery_h = 0;
uint8_t Status_Battery = 0;

uint32_t deb_fmdem_l = 0;
uint32_t deb_fmdem_h = 0;
uint8_t Status_FMDem = 0;

uint32_t deb_stmo_l = 0;
uint32_t deb_stmo_h = 0;
uint8_t Status_Stereo = 0;

reset_cause_t reset_cause;

uint32_t TelaAtiva = 0;
uint32_t filter_adc = 0;
uint32_t filter_adc3 = 0;

double STM32Temperature;

/* Variable containing ADC conversions data */
//ALIGN_32BYTES (static uint16_t   adcBuffer[8]);
#define ADC_CONVERTED_DATA_BUFFER_SIZE   ((uint32_t)  8)   /* Size of array aADCxConvertedData[] */
ALIGN_32BYTES (static uint16_t   adcBuffer[ADC_CONVERTED_DATA_BUFFER_SIZE]);
ALIGN_32BYTES (static uint16_t   adc3Buffer[ADC_CONVERTED_DATA_BUFFER_SIZE]) __attribute__((section(".RAM_D3")));
uint16_t adcH7[] = {0};
uint16_t adc_ext[11] = {0};

// Variaveis para valores convertidos
volatile uint16_t adc_values[8];
volatile uint8_t adc_ready = 0;

/* USER CODE END PV */

void SystemClock_Config(void);
void PeriphCommonClock_Config(void);
static void MPU_Config(void);
void MX_FREERTOS_Init(void);

int main(void)
{

  /* MPU Configuration--------------------------------------------------------*/
  MPU_Config();

  /* Enable the CPU Cache */

  /* Enable I-Cache---------------------------------------------------------*/
  SCB_EnableICache();

  /* Enable D-Cache---------------------------------------------------------*/
  SCB_EnableDCache();

  /* MCU Configuration--------------------------------------------------------*/

  /* Reset of all peripherals, Initializes the Flash interface and the Systick. */
  HAL_Init();

  /* Configure the system clock */
  SystemClock_Config();

  /* Configure the peripherals common clocks */
  PeriphCommonClock_Config();

  /* Initialize all configured peripherals */
  MX_GPIO_Init();
  MX_DMA_Init();
  MX_BDMA_Init();
  //MX_MDMA_Init();
  MX_FMC_Init();
  MX_I2C1_Init();
  MX_QUADSPI_Init();
  MX_RTC_Init();
  MX_TIM1_Init();
  MX_TIM12_Init();
  MX_IWDG1_Init();
  MX_CRC_Init();
  MX_RNG_Init();
  MX_ADC1_Init();
  MX_ADC3_Init();
  MX_I2S2_Init();
  MX_DMA2D_Init();
  /* Call PreOsInit function */
  //MX_MBEDTLS_Init();
  /* USER CODE BEGIN 2 */
  __HAL_RCC_D2SRAM1_CLK_ENABLE();
  __HAL_RCC_D2SRAM2_CLK_ENABLE();
  __HAL_RCC_D2SRAM3_CLK_ENABLE();
  __HAL_RCC_BKPRAM_CLKAM_ENABLE();

  // LEDS
  HAL_GPIO_WritePin(LED_FAIL_GPIO_Port, LED_FAIL_Pin, LED_OFF);		// LED FAIL OFF
  HAL_GPIO_WritePin(LED_LOCK_GPIO_Port, LED_LOCK_Pin, LED_OFF);		// LED LOCK OFF
  HAL_GPIO_WritePin(LED_RSSI_GPIO_Port, LED_RSSI_Pin, LED_OFF);		// LED RF OFF

  HAL_TIM_Base_Start_IT(&htim12);
  HAL_TIM_PWM_Start(&htim1, TIM_CHANNEL_1);
  __HAL_TIM_SetCompare(&htim1, TIM_CHANNEL_1, 0);		// PWM_CH1 = 0      RF
  __HAL_DBGMCU_FREEZE_IWDG1();

  // Calibrate RTC
 // HAL_RTCEx_SetSmoothCalib(&hrtc, RTC_SMOOTHCALIB_PERIOD_32SEC, 1, 500);

  // Config ADC
  adc_ext[0] = 0;
  adc_ext[1] = 0;
  adc_ext[2] = 0;
  adc_ext[3] = 0;
  adc_ext[4] = 0;
  adc_ext[5] = 0;
  adc_ext[6] = 0;
  adc_ext[7] = 0;
  adc_ext[8] = 0;
  adc_ext[9] = 0;

  // Start ADC 1 Calibration
  HAL_ADC_Stop(&hadc1);
  if (HAL_ADCEx_Calibration_Start(&hadc1, ADC_CALIB_OFFSET, ADC_SINGLE_ENDED) != HAL_OK)
  {
      // A calibracao falhou, trate o erro.
      Error_Handler();
  }

  if(HAL_ADCEx_Calibration_Start(&hadc1, ADC_CALIB_OFFSET_LINEARITY, ADC_SINGLE_ENDED) != HAL_OK) {
	  Error_Handler();
  }
  // Start ADC in DMA
  if(HAL_ADC_Start_DMA(&hadc1, (uint32_t *)adcBuffer, 8) != HAL_OK) {
	  Error_Handler();
  }

  // Start ADC 3 Calibration
  HAL_ADC_Stop(&hadc3);
  if (HAL_ADCEx_Calibration_Start(&hadc3, ADC_CALIB_OFFSET, ADC_SINGLE_ENDED) != HAL_OK)
  {
      // A calibracao falhou, trate o erro.
      Error_Handler();
  }

  if(HAL_ADCEx_Calibration_Start(&hadc3, ADC_CALIB_OFFSET_LINEARITY, ADC_SINGLE_ENDED) != HAL_OK) {
	  Error_Handler();
  }
  // Start ADC in DMA
  if(HAL_ADC_Start_DMA(&hadc3, (uint32_t *)adc3Buffer, 3) != HAL_OK) {
	  Error_Handler();
  }

  // Causa Reset
  reset_cause = reset_cause_get();

  // Inicia Buzzer Vars
  Buzzer_init();

  // Init SSD1963
  drv_ssd1963_init();
  drv_ssd1963_SetBacklight(200);
  // Tela de Start-UP
  drv_ssd1963_bmp();
  /* USER CODE END 2 */

  /* Init scheduler */
  osKernelInitialize();  /* Call init function for freertos objects (in cmsis_os2.c) */
  MX_FREERTOS_Init();

  /* Start scheduler */
  osKernelStart();

  /* We should never get here as control is now taken by the scheduler */

  /* Infinite loop */
  while (1)
  {

  }
}

void SystemClock_Config(void)
{
  RCC_OscInitTypeDef RCC_OscInitStruct = {0};
  RCC_ClkInitTypeDef RCC_ClkInitStruct = {0};

  /** Supply configuration update enable
  */
  HAL_PWREx_ConfigSupply(PWR_LDO_SUPPLY);

  /** Configure the main internal regulator output voltage
  */
  __HAL_PWR_VOLTAGESCALING_CONFIG(PWR_REGULATOR_VOLTAGE_SCALE0);

  while(!__HAL_PWR_GET_FLAG(PWR_FLAG_VOSRDY)) {}

  /** Configure LSE Drive Capability
  */
  HAL_PWR_EnableBkUpAccess();
  __HAL_RCC_LSEDRIVE_CONFIG(RCC_LSEDRIVE_HIGH);

  /** Initializes the RCC Oscillators according to the specified parameters
  * in the RCC_OscInitTypeDef structure.
  */
  RCC_OscInitStruct.OscillatorType = RCC_OSCILLATORTYPE_LSI|RCC_OSCILLATORTYPE_HSE
                              |RCC_OSCILLATORTYPE_LSE;
  RCC_OscInitStruct.HSEState = RCC_HSE_ON;
  RCC_OscInitStruct.LSEState = RCC_LSE_ON;
  RCC_OscInitStruct.LSIState = RCC_LSI_ON;
  RCC_OscInitStruct.PLL.PLLState = RCC_PLL_ON;
  RCC_OscInitStruct.PLL.PLLSource = RCC_PLLSOURCE_HSE;
  RCC_OscInitStruct.PLL.PLLM = 4;
  RCC_OscInitStruct.PLL.PLLN = 480;
  RCC_OscInitStruct.PLL.PLLP = 2;
  RCC_OscInitStruct.PLL.PLLQ = 8;
  RCC_OscInitStruct.PLL.PLLR = 8;
  RCC_OscInitStruct.PLL.PLLRGE = RCC_PLL1VCIRANGE_1;
  RCC_OscInitStruct.PLL.PLLVCOSEL = RCC_PLL1VCOWIDE;
  RCC_OscInitStruct.PLL.PLLFRACN = 0;
  if (HAL_RCC_OscConfig(&RCC_OscInitStruct) != HAL_OK)
  {
    Error_Handler();
  }

  /** Initializes the CPU, AHB and APB buses clocks
  */
  RCC_ClkInitStruct.ClockType = RCC_CLOCKTYPE_HCLK|RCC_CLOCKTYPE_SYSCLK
                              |RCC_CLOCKTYPE_PCLK1|RCC_CLOCKTYPE_PCLK2
                              |RCC_CLOCKTYPE_D3PCLK1|RCC_CLOCKTYPE_D1PCLK1;
  RCC_ClkInitStruct.SYSCLKSource = RCC_SYSCLKSOURCE_PLLCLK;
  RCC_ClkInitStruct.SYSCLKDivider = RCC_SYSCLK_DIV1;
  RCC_ClkInitStruct.AHBCLKDivider = RCC_HCLK_DIV2;
  RCC_ClkInitStruct.APB3CLKDivider = RCC_APB3_DIV2;
  RCC_ClkInitStruct.APB1CLKDivider = RCC_APB1_DIV2;
  RCC_ClkInitStruct.APB2CLKDivider = RCC_APB2_DIV2;
  RCC_ClkInitStruct.APB4CLKDivider = RCC_APB4_DIV2;

  if (HAL_RCC_ClockConfig(&RCC_ClkInitStruct, FLASH_LATENCY_4) != HAL_OK)
  {
    Error_Handler();
  }
}

void PeriphCommonClock_Config(void)
{
  RCC_PeriphCLKInitTypeDef PeriphClkInitStruct = {0};

  /** Initializes the peripherals clock
  */
  PeriphClkInitStruct.PeriphClockSelection = RCC_PERIPHCLK_FMC|RCC_PERIPHCLK_QSPI
                              |RCC_PERIPHCLK_USB|RCC_PERIPHCLK_ADC;
  PeriphClkInitStruct.PLL2.PLL2M = 4;
  PeriphClkInitStruct.PLL2.PLL2N = 480;
  PeriphClkInitStruct.PLL2.PLL2P = 2;
  PeriphClkInitStruct.PLL2.PLL2Q = 2;
  PeriphClkInitStruct.PLL2.PLL2R = 8;
  PeriphClkInitStruct.PLL2.PLL2RGE = RCC_PLL2VCIRANGE_1;
  PeriphClkInitStruct.PLL2.PLL2VCOSEL = RCC_PLL2VCOWIDE;
  PeriphClkInitStruct.PLL2.PLL2FRACN = 0;
  PeriphClkInitStruct.PLL3.PLL3M = 4;
  PeriphClkInitStruct.PLL3.PLL3N = 480;
  PeriphClkInitStruct.PLL3.PLL3P = 2;
  PeriphClkInitStruct.PLL3.PLL3Q = 20;
  PeriphClkInitStruct.PLL3.PLL3R = 10;
  PeriphClkInitStruct.PLL3.PLL3RGE = RCC_PLL3VCIRANGE_1;
  PeriphClkInitStruct.PLL3.PLL3VCOSEL = RCC_PLL3VCOWIDE;
  PeriphClkInitStruct.PLL3.PLL3FRACN = 0;
  PeriphClkInitStruct.FmcClockSelection = RCC_FMCCLKSOURCE_PLL2;
  PeriphClkInitStruct.QspiClockSelection = RCC_QSPICLKSOURCE_PLL2;
  PeriphClkInitStruct.UsbClockSelection = RCC_USBCLKSOURCE_PLL3;
  PeriphClkInitStruct.AdcClockSelection = RCC_ADCCLKSOURCE_PLL3;
  if (HAL_RCCEx_PeriphCLKConfig(&PeriphClkInitStruct) != HAL_OK)
  {
    Error_Handler();
  }
}

/* USER CODE BEGIN 4 */
int _gettimeofday( struct timeval *tv, void *tzvp )
{
    // you can add code here there many example in google search.
    return 0;  // return non-zero for error
} // end _gettimeofday()

reset_cause_t reset_cause_get(void)
{
    reset_cause_t reset_cause;

//    if (__HAL_RCC_GET_FLAG(RCC_FLAG_LPWRRST))
//    {
//        reset_cause = RESET_CAUSE_LOW_POWER_RESET;
//    }
    if (__HAL_RCC_GET_FLAG(RCC_FLAG_WWDG1RST))
    {
        reset_cause = RESET_CAUSE_WINDOW_WATCHDOG_RESET;
    }
    else if (__HAL_RCC_GET_FLAG(RCC_FLAG_IWDG1RST))
    {
        reset_cause = RESET_CAUSE_INDEPENDENT_WATCHDOG_RESET;
    }
    else if (__HAL_RCC_GET_FLAG(RCC_FLAG_SFTRST))
    {
        reset_cause = RESET_CAUSE_SOFTWARE_RESET; // This reset is induced by calling the ARM CMSIS `NVIC_SystemReset()` function!
    }
    else if (__HAL_RCC_GET_FLAG(RCC_FLAG_PORRST))
    {
        reset_cause = RESET_CAUSE_POWER_ON_POWER_DOWN_RESET;
    }
    else if (__HAL_RCC_GET_FLAG(RCC_FLAG_PINRST))
    {
        reset_cause = RESET_CAUSE_EXTERNAL_RESET_PIN_RESET;
    }
    // Needs to come *after* checking the `RCC_FLAG_PORRST` flag in order to ensure first that the reset cause is
    // NOT a POR/PDR reset. See note below.
    else if (__HAL_RCC_GET_FLAG(RCC_FLAG_BORRST))
    {
        reset_cause = RESET_CAUSE_BROWNOUT_RESET;
    }
    else
    {
        reset_cause = RESET_CAUSE_UNKNOWN;
    }

    // Clear all the reset flags or else they will remain set during future resets until system power is fully removed.
    __HAL_RCC_CLEAR_RESET_FLAGS();

    return reset_cause;
}

#ifdef __GNUC__
  /* With GCC, small printf (option LD Linker->Libraries->Small printf
     set to 'Yes') calls __io_putchar() */
//  #define PUTCHAR_PROTOTYPE int __io_putchar(int ch)
#else
  #define PUTCHAR_PROTOTYPE int fputc(int ch, FILE *f)
#endif /* __GNUC__ */
//PUTCHAR_PROTOTYPE
//{
//  /* Place your implementation of fputc here */
//  /* e.g. write a character to the EVAL_COM1 and Loop until the end of transmission */
//  //HAL_UART_Transmit(&huart3, (uint8_t *)&ch, 1, 0xFFFF);
//  CDC_Transmit_FS((uint8_t*)&ch, 1);
//
//  return ch;
//}
int _write(int fd, char * ptr, int len)
{
  //CDC_Transmit_FS((uint8_t *) ptr, len);
  return len;
}

void Read_Remote(void)
{
	// Debounce Battery Input
	BatteryInput = HAL_GPIO_ReadPin(DET_BAT_GPIO_Port, DET_BAT_Pin);
	if(BatteryInput == GPIO_PIN_RESET) {
		deb_battery_l++;
		deb_battery_h = 0;
		if(deb_battery_l >= DEBOUNCE_REMOTE) {
			deb_battery_l = DEBOUNCE_REMOTE + 1;
			Status_Battery = 0;
		}
	}
	else {
		deb_battery_h++;
		deb_battery_l = 0;
		if(deb_battery_h >= DEBOUNCE_REMOTE) {
			deb_battery_h = DEBOUNCE_REMOTE + 1;
			Status_Battery = 1;
		}
	}
	// FM Demulador
	FMDemInput = HAL_GPIO_ReadPin(FM_DEM_GPIO_Port, FM_DEM_Pin);
	if(FMDemInput == GPIO_PIN_RESET) {
		deb_fmdem_l++;
		deb_fmdem_h = 0;
		if(deb_fmdem_l >= DEBOUNCE_REMOTE) {
			deb_fmdem_l = DEBOUNCE_REMOTE + 1;
			Status_FMDem = 0;
		}
	}
	else {
		deb_fmdem_h++;
		deb_fmdem_l = 0;
		if(deb_fmdem_h >= DEBOUNCE_REMOTE) {
			deb_fmdem_h = DEBOUNCE_REMOTE + 1;
			Status_FMDem = 1;
		}
	}
	// Stereo / Mono
	StereoMonoInput = HAL_GPIO_ReadPin(ST_MO_GPIO_Port, ST_MO_Pin);
	if(StereoMonoInput == GPIO_PIN_RESET) {
		deb_stmo_l++;
		deb_stmo_h = 0;
		if(deb_stmo_l >= DEBOUNCE_REMOTE) {
			deb_stmo_l = DEBOUNCE_REMOTE + 1;
			Status_Stereo = 0;
		}
	}
	else {
		deb_stmo_h++;
		deb_stmo_l = 0;
		if(deb_stmo_h >= DEBOUNCE_REMOTE) {
			deb_stmo_h = DEBOUNCE_REMOTE + 1;
			Status_Stereo = 1;
		}
	}
}

/**
  * @brief  Conversion complete callback in non-blocking mode
  * @param  hadc: ADC handle
  * @retval None
  */
void HAL_ADC_ConvHalfCpltCallback(ADC_HandleTypeDef* hadc)
{
  /* Invalidate Data Cache to get the updated content of the SRAM on the first half of the ADC converted data buffer: 32 bytes */
//  SCB_InvalidateDCache_by_Addr((uint32_t *)adcBuffer, sizeof(adcBuffer) / 2);
}

/**
  * @brief  Conversion DMA half-transfer callback in non-blocking mode
  * @param  hadc: ADC handle
  * @retval None
  */
void HAL_ADC_ConvCpltCallback(ADC_HandleTypeDef* hadc)
{
	if(hadc->Instance == ADC1) {
		/* Invalidate Data Cache to get the updated content of the SRAM on the second half of the ADC converted data buffer: 32 bytes */
		// Copia os valores do buffer para o array principal
		for (int i = 0; i < 8; i++) {
			adc_values[i] = adcBuffer[i];
		}
		adc_ready = 1;
		filter_adc++;
	}
	if(hadc->Instance == ADC3) {
		filter_adc3++;
	}
}

// Callback de erro
void HAL_ADC_ErrorCallback(ADC_HandleTypeDef *hadc)
{
	if(hadc->Instance == ADC1) {
		// Tratamento de erro - pode reiniciar a conversao
		HAL_ADC_Stop_DMA(&hadc1);
		HAL_ADC_Start_DMA(&hadc1, (uint32_t*)adcBuffer, 8);
	}
	if(hadc->Instance == ADC3) {
		// Tratamento de erro - pode reiniciar a conversao
		HAL_ADC_Stop_DMA(&hadc3);
		HAL_ADC_Start_DMA(&hadc3, (uint32_t*)adc3Buffer, 3);
	}
}

void MCU_TemperatureCalculate(uint32_t GetValue)
{
	uint32_t T1_30 = (uint32_t) *TEMPSENSOR_CAL1_ADDR;		// @30C
	uint32_t T1_110 = (uint32_t) *TEMPSENSOR_CAL2_ADDR;		// @110C

	//calculate the temperature in (in °C)
	// Analog-to-digital converters (ADC)
	// Temperature (in °C) = ((110 °C – 30 °C)/(TS_CAL2 – TS_CAL1))× (TS_DATA – TS_CAL1) + 30 °C
	STM32Temperature = ( (((double)(110 - 30))/((double)(T1_110 - T1_30))) * ((double)(GetValue - T1_30)) ) + ((double)30);
}

void MCU_Temperature(void)
{
	MCU_TemperatureCalculate(adc3Buffer[0]);
}
/* USER CODE END 4 */

 /* MPU Configuration */

void MPU_Config(void)
{
  MPU_Region_InitTypeDef MPU_InitStruct = {0};

  /* Disables the MPU */
  HAL_MPU_Disable();

  /** Initializes and configures the Region and the memory to be protected
  */
  MPU_InitStruct.Enable = MPU_REGION_ENABLE;
  MPU_InitStruct.Number = MPU_REGION_NUMBER0;
  MPU_InitStruct.BaseAddress = 0x0;
  MPU_InitStruct.Size = MPU_REGION_SIZE_4GB;
  MPU_InitStruct.SubRegionDisable = 0x87;
  MPU_InitStruct.TypeExtField = MPU_TEX_LEVEL0;
  MPU_InitStruct.AccessPermission = MPU_REGION_NO_ACCESS;
  MPU_InitStruct.DisableExec = MPU_INSTRUCTION_ACCESS_DISABLE;
  MPU_InitStruct.IsShareable = MPU_ACCESS_SHAREABLE;
  MPU_InitStruct.IsCacheable = MPU_ACCESS_NOT_CACHEABLE;
  MPU_InitStruct.IsBufferable = MPU_ACCESS_NOT_BUFFERABLE;

  HAL_MPU_ConfigRegion(&MPU_InitStruct);

  /** Initializes and configures the Region and the memory to be protected
  */
  MPU_InitStruct.Number = MPU_REGION_NUMBER1;
  MPU_InitStruct.BaseAddress = 0x30020000;
  MPU_InitStruct.Size = MPU_REGION_SIZE_128KB;
  MPU_InitStruct.SubRegionDisable = 0x0;
  MPU_InitStruct.TypeExtField = MPU_TEX_LEVEL1;
  MPU_InitStruct.AccessPermission = MPU_REGION_FULL_ACCESS;
  MPU_InitStruct.IsShareable = MPU_ACCESS_NOT_SHAREABLE;

  HAL_MPU_ConfigRegion(&MPU_InitStruct);

  /** Initializes and configures the Region and the memory to be protected
  */
  MPU_InitStruct.Number = MPU_REGION_NUMBER2;
  MPU_InitStruct.BaseAddress = 0x30040000;
  MPU_InitStruct.Size = MPU_REGION_SIZE_512B;
  MPU_InitStruct.TypeExtField = MPU_TEX_LEVEL0;
  MPU_InitStruct.IsShareable = MPU_ACCESS_SHAREABLE;
  MPU_InitStruct.IsBufferable = MPU_ACCESS_BUFFERABLE;

  HAL_MPU_ConfigRegion(&MPU_InitStruct);

  /** Initializes and configures the Region and the memory to be protected
  */
  MPU_InitStruct.Number = MPU_REGION_NUMBER3;
  MPU_InitStruct.BaseAddress = 0x60000000;
  MPU_InitStruct.Size = MPU_REGION_SIZE_4KB;
  MPU_InitStruct.IsShareable = MPU_ACCESS_NOT_SHAREABLE;
  MPU_InitStruct.IsBufferable = MPU_ACCESS_NOT_BUFFERABLE;

  HAL_MPU_ConfigRegion(&MPU_InitStruct);

  /** Initializes and configures the Region and the memory to be protected
  */
  MPU_InitStruct.Number = MPU_REGION_NUMBER4;
  MPU_InitStruct.BaseAddress = 0x60080000;

  HAL_MPU_ConfigRegion(&MPU_InitStruct);

  // RAM_D1
  //MPU_InitStruct.Enable = MPU_REGION_ENABLE;
  //MPU_InitStruct.BaseAddress = 0x24000000;
  //MPU_InitStruct.Size = MPU_REGION_SIZE_512KB;
  //MPU_InitStruct.AccessPermission = MPU_REGION_FULL_ACCESS;
  //MPU_InitStruct.IsCacheable = MPU_ACCESS_NOT_CACHEABLE;
  //MPU_InitStruct.IsBufferable = MPU_ACCESS_NOT_BUFFERABLE;
  //HAL_MPU_ConfigRegion(&MPU_InitStruct);

  /* Enables the MPU */
  HAL_MPU_Enable(MPU_PRIVILEGED_DEFAULT);

}

void HAL_TIM_PeriodElapsedCallback(TIM_HandleTypeDef *htim)
{
  if (htim->Instance == TIM6)
  {
    HAL_IncTick();
  }
  /* USER CODE BEGIN Callback 1 */
  if (htim->Instance == TIM12) {
	  ulHighFrequencyTimerTicks++;
	  // Controle Buzzer
	  Buzzer_Run();
  }

  if (htim->Instance == TIM6) {
	  MilliTimer++;

	  timer_lvgl++;
	  if(timer_lvgl >= 10) {
		  timer_lvgl = 0;
		  lv_tick_inc(10);
	  }

	  timer_key++;
	  if(timer_key >= PUSHBTN_TMR_PERIOD) {
		  timer_key = 0;
		  Key_Read();
	  }
  }
  /* USER CODE END Callback 1 */
}

void Error_Handler(void)
{
  __disable_irq();
  while (1)
  {
  }
}

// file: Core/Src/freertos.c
/* USER CODE BEGIN Header */
/**
  ******************************************************************************
  * File Name          : freertos.c
  * Description        : Code for freertos applications
  ******************************************************************************
  * @attention
  *
  * Copyright (c) 2025 STMicroelectronics.
  * All rights reserved.
  *
  * This software is licensed under terms that can be found in the LICENSE file
  * in the root directory of this software component.
  * If no LICENSE file comes with this software, it is provided AS-IS.
  *
  ******************************************************************************
  */
/* USER CODE END Header */

#include "FreeRTOS.h"
#include "task.h"
#include "main.h"
#include "cmsis_os.h"
#include "i2s.h"

/* USER CODE BEGIN Includes */
#include <time.h>
#include "iwdg.h"
#include "queue.h"
#include "semphr.h"
#include "stdio.h"
#include "string.h"
#include "tim.h"
#include "rtc.h"
#include "fatfs.h"
#include "mbedtls.h"
#include "lwip/apps/lwiperf.h"
#include "lwip/apps/httpd.h"
#include "lwip/apps/snmp.h"
#include "lwip/apps/snmpv3.h"
#include "lwip/apps/sntp.h"
//#include "lwip/netconn.h"

#include "ethernetif.h"
#include "lwip/netif.h"
#include "lwip/tcpip.h"

#include "../Sinteck/src/uuid.h"
#include "../Sinteck/display/Drv_SSD1963.h"
#include "../Sinteck/src/stm32_qspi_512.h"
#include "../Sinteck/src/SAA6579.h"
#include "../Sinteck/src/TPA6130A2.h"
#include "../Sinteck/lvgl/lvgl.h"
#include "../Sinteck/lv_fs_if/lv_fs_if.h"
#include "../Sinteck/tcp/httpserver_netconn.h"
#include "../Sinteck/tcp/mqtt_paho.h"
#include "../Sinteck/tcp/snmp_app.h"
#include "../Sinteck/tcp/mqtt_client.h"

#include "../Sinteck/src/audio.h"
#include "../Sinteck/src/sine_generator.h"
#include "../Sinteck/src/file_handling.h"
#include "../Sinteck/src/keys.h"
#include "../Sinteck/src/buzzer.h"
#include "../Sinteck/src/eeprom.h"
#include "../Sinteck/src/defines.h"
#include "../Sinteck/src/wav_player.h"

#include <GUI/screen_main_TX.h>
#include <GUI/screen_main_RX.h>

#include "mp3dec.h"

/* USER CODE END Includes */

/* USER CODE BEGIN PTD */
extern RTC_DateTypeDef gDateAdj;
extern RTC_TimeTypeDef gTimeAdj;

#define NTP_SERVER "pool.ntp.org"
//#define NTP_SERVER "a.st1.ntp.br"
#define NTP_PORT 123
#define NTP_TIMEOUT 5000
#define NTP_RETRY_DELAY 3000

const int fuso_offset[25] = { -12, -11, -10, -9, -8, -7, -6, -5, -4, -3, -2, -1, 0, 1, 2, 3, 4, 5, 6, 7, 8, 9, 10, 11, 12 };

// Estrutura do pacote NTP (RFC 2030)
typedef struct {
    uint8_t li_vn_mode;
    uint8_t stratum;
    uint8_t poll;
    uint8_t precision;
    uint32_t root_delay;
    uint32_t root_dispersion;
    uint32_t reference_id;
    uint32_t ref_ts_sec;
    uint32_t ref_ts_frac;
    uint32_t orig_ts_sec;
    uint32_t orig_ts_frac;
    uint32_t recv_ts_sec;
    uint32_t recv_ts_frac;
    uint32_t trans_ts_sec;
    uint32_t trans_ts_frac;
} ntp_packet_t;

#define NTP_OFFSET 2208988800U  // Segundos entre 1900 e 1970
char str_ntp[256] = {0};

extern volatile uint8_t rx_uart[];

void Read_Remote(void);
extern void MX_LWIP_Init(void);
extern void MX_USB_DEVICE_Init(void);
extern void MCU_Temperature(void);
void Mount_FATFS_QSPI(void);
void my_loglvgl(lv_log_level_t level, const char *file, uint32_t line, const char *dsc);
void FillI2SBuffer(int32_t *i2s_buffer, short *pcm);
void TaskDecoder(void *argument);
void TaskAudio(void *argument);

volatile unsigned long ulHighFrequencyTimerTicks = 0;

double STM32_Temp = 0;

unsigned char readBuffer[8192]; 						// Buffer de leitura (SD/Flash)
short outBuffer[MAX_NCHAN * MAX_NGRAN * MAX_NSAMP]; 	// Buffer PCM de saída

lv_disp_buf_t disp_buf;

// Use atributos para forçar a alocação na RAM D1 (A MAIS RÁPIDA)
// E alinhe o buffer para 32 bytes para otimização de Cache
lv_color_t lvgl_buf_1[LV_HOR_RES_MAX * 16] __attribute__((section(".RAM_D1"))) __attribute__((aligned(32)));

// (Opcional, mas recomendado: buffer duplo)
lv_color_t lvgl_buf_2[LV_HOR_RES_MAX * 16] __attribute__((section(".RAM_D1"))) __attribute__((aligned(32)));

lv_mem_monitor_t mon;

FATFS *pfs;
char line[1024*8]; /* Line buffer */
FRESULT fr;     /* FatFs return code */
DWORD fre_clust;
uint32_t totalSpace, freeSpace, SpaceUsed;

// FLASH QSPI W25Q512
extern uint8_t retUSER;    /* Return value for USER */
extern FATFS USERFatFS;    /* File system object for USER  cal drive */
extern FIL USERFile;       /* File object for USER */
extern char USERPath[4];

// USB HOST
extern uint8_t retUSBH;    /* Return value for USBH */
extern FATFS USBHFatFS;    /* File system object for USBH logical drive */
extern FIL USBHFile;       /* File object for USBH */
extern char USBHPath[4];

lv_mem_monitor_t mon;

uint8_t qspi_ret;
uint32_t duracao = 0;
uint32_t size;
unsigned int ByteRead;
char version_flash[32] = {0};
uint32_t timer_alarm_lvgl = 0;
uint32_t timer_read_rtc = 0;

RTC_DateTypeDef gDate;
RTC_TimeTypeDef gTime;
SYS_DateTime TimeInicio;
extern SYS_Realtime Realtime;

uint8_t Telemetry_State = 0;
uint32_t timer_teste = 0;
uint32_t rds_report = 0;

extern Cfg_var cfg;
extern license_var lic;
extern Profile_var Profile;

/* USER CODE END PTD */

/* Definitions for TaskMain */
osThreadId_t TaskMainHandle;
const osThreadAttr_t TaskMain_attributes = {
  .name = "TaskMain",
  .stack_size = 1024 * 4,
  .priority = (osPriority_t) osPriorityNormal2,
};
/* Definitions for TaskGUI */
osThreadId_t TaskGUIHandle;
const osThreadAttr_t TaskGUI_attributes = {
  .name = "TaskGUI",
  .stack_size = 4096 * 4,
  .priority = (osPriority_t) osPriorityLow,
};
/* Definitions for TaskNTP */
osThreadId_t TaskNTPHandle;
const osThreadAttr_t TaskNTP_attributes = {
  .name = "TaskNTP",
  .stack_size = 1024 * 4,
  .priority = (osPriority_t) osPriorityNormal,
};
/* Definitions for QueueUSART3 */
osMessageQueueId_t QueueUSART3Handle;
const osMessageQueueAttr_t QueueUSART3_attributes = {
  .name = "QueueUSART3"
};
/* Definitions for QueueUSART6 */
osMessageQueueId_t QueueUSART6Handle;
const osMessageQueueAttr_t QueueUSART6_attributes = {
  .name = "QueueUSART6"
};
/* Definitions for QueueBuzzer */
osMessageQueueId_t QueueBuzzerHandle;
const osMessageQueueAttr_t QueueBuzzer_attributes = {
  .name = "QueueBuzzer"
};
/* Definitions for QueueHttp */
osMessageQueueId_t QueueHttpHandle;
const osMessageQueueAttr_t QueueHttp_attributes = {
  .name = "QueueHttp"
};
/* Definitions for QueueMqtt */
osMessageQueueId_t QueueMqttHandle;
const osMessageQueueAttr_t QueueMqtt_attributes = {
  .name = "QueueMqtt"
};
/* Definitions for MutexI2C */
osMutexId_t MutexI2CHandle;
const osMutexAttr_t MutexI2C_attributes = {
  .name = "MutexI2C"
};
/* Definitions for MutexLVGL */
osMutexId_t MutexLVGLHandle;
const osMutexAttr_t MutexLVGL_attributes = {
  .name = "MutexLVGL"
};
/* Definitions for MutexHTTPD */
osMutexId_t MutexHTTPDHandle;
const osMutexAttr_t MutexHTTPD_attributes = {
  .name = "MutexHTTPD"
};
/* Definitions for MutexMQTT */
osMutexId_t MutexMqtt;
const osMutexAttr_t MutexMqtt_attributes = {
  .name = "MutexMqtt"
};

/* Definitions for BinarySemI2C */
osSemaphoreId_t BinarySemI2CHandle;
const osSemaphoreAttr_t BinarySemI2C_attributes = {
  .name = "BinarySemI2C"
};
/* Definitions for BinarySemLVGL */
osSemaphoreId_t BinarySemLVGLHandle;
const osSemaphoreAttr_t BinarySemLVGL_attributes = {
  .name = "BinarySemLVGL"
};
/* Definitions for BinarySemHTTPD */
osSemaphoreId_t BinarySemHTTPDHandle;
const osSemaphoreAttr_t BinarySemHTTPD_attributes = {
  .name = "BinarySemHTTPD"
};
/* Definitions for BinarySemMQTT */
osSemaphoreId_t BinarySemMQTTHandle;
const osSemaphoreAttr_t BinarySemMQTT_attributes = {
  .name = "BinarySemMQTT"
};

void StartTaskMain(void *argument);
void StartTaskGUI(void *argument);
void StartTaskNTP(void *argument);

extern void MX_LWIP_Init(void);
extern void MX_USB_HOST_Init(void);
void MX_FREERTOS_Init(void); /* (MISRA C 2004 rule 8.1) */

/* Hook prototypes */
void configureTimerForRunTimeStats(void);
unsigned long getRunTimeCounterValue(void);
void vApplicationStackOverflowHook(xTaskHandle xTask, signed char *pcTaskName);

/* USER CODE BEGIN 1 */
/* Functions needed when configGENERATE_RUN_TIME_STATS is on */
__weak void configureTimerForRunTimeStats(void)
{
	ulHighFrequencyTimerTicks = 0;
}

__weak unsigned long getRunTimeCounterValue(void)
{
	return ulHighFrequencyTimerTicks;
}
/* USER CODE END 1 */

/* USER CODE BEGIN 4 */
void vApplicationStackOverflowHook(xTaskHandle xTask, signed char *pcTaskName)
{
   /* Run time stack overflow checking is performed if
   configCHECK_FOR_STACK_OVERFLOW is defined to 1 or 2. This hook function is
   called if a stack overflow is detected. */
}
/* USER CODE END 4 */

void MX_FREERTOS_Init(void) {
  /* Create the mutex(es) */
  /* creation of MutexI2C */
  MutexI2CHandle = osMutexNew(&MutexI2C_attributes);

  /* creation of MutexLVGL */
  MutexLVGLHandle = osMutexNew(&MutexLVGL_attributes);

  /* creation of MutexHTTPD */
  MutexHTTPDHandle = osMutexNew(&MutexHTTPD_attributes);

  /* creation of MutexMqtt */
  MutexMqtt = osMutexNew(&MutexMqtt_attributes);

  /* Create the semaphores(s) */
  /* creation of BinarySemI2C */
  BinarySemI2CHandle = osSemaphoreNew(1, 0, &BinarySemI2C_attributes);

  /* creation of BinarySemLVGL */
  BinarySemLVGLHandle = osSemaphoreNew(1, 0, &BinarySemLVGL_attributes);

  /* creation of BinarySemHTTPD */
  BinarySemHTTPDHandle = osSemaphoreNew(1, 0, &BinarySemHTTPD_attributes);

  /* creation of BinarySemMQTT */
  BinarySemMQTTHandle = osSemaphoreNew(1, 1, &BinarySemMQTT_attributes);

  /* Create the queue(s) */
  /* creation of QueueUSART3 */
  QueueUSART3Handle = osMessageQueueNew (16, sizeof(uint8_t), &QueueUSART3_attributes);

  /* creation of QueueUSART6 */
  QueueUSART6Handle = osMessageQueueNew (16, sizeof(uint8_t), &QueueUSART6_attributes);

  /* creation of QueueBuzzer */
  QueueBuzzerHandle = osMessageQueueNew (1, sizeof(uint32_t), &QueueBuzzer_attributes);

  /* creation of QueueHttp */
  QueueHttpHandle = osMessageQueueNew (1, sizeof(uint32_t), &QueueHttp_attributes);

  /* creation of QueueMqtt */
  QueueMqttHandle = osMessageQueueNew (50, 10, &QueueMqtt_attributes);

  /* Create the thread(s) */
  /* creation of TaskMain */
  TaskMainHandle = osThreadNew(StartTaskMain, NULL, &TaskMain_attributes);

  /* creation of TaskGUI */
  TaskGUIHandle = osThreadNew(StartTaskGUI, NULL, &TaskGUI_attributes);

  /* creation of TaskNTP */
  TaskNTPHandle = osThreadNew(StartTaskNTP, NULL, &TaskNTP_attributes);

  Audio_Player_Init();
  //Send_teste_1khz();
}

void StartTaskMain(void *argument)
{
  /* init code for USB_HOST */
  MX_USB_HOST_Init();
  /* USER CODE BEGIN StartTaskMain */

  // Grava Hora de Inicio
  // Get the RTC current Time
  HAL_PWR_EnableBkUpAccess();
  __HAL_RCC_BKPRAM_CLK_ENABLE();
  HAL_RTC_GetTime(&hrtc, &gTime, RTC_FORMAT_BIN);
  // Get the RTC current Date */
  HAL_RTC_GetDate(&hrtc, &gDate, RTC_FORMAT_BIN);
  __HAL_RCC_BKPRAM_CLK_DISABLE();
  HAL_PWR_DisableBkUpAccess();

  TimeInicio.day = gDate.Date;
  TimeInicio.month = gDate.Month;
  TimeInicio.year = 2000+gDate.Year;
  TimeInicio.hour = gTime.Hours;
  TimeInicio.minute = gTime.Minutes;
  TimeInicio.second = gTime.Seconds;
  TimeInicio.total = (gTime.Hours * 3600) + (gTime.Minutes * 60) + gTime.Seconds;

  // Carrega Programacao da EEPROM
  cfg.EepromID = 0xFFFF;
  cfg.prg_rev  = 0xFFFF;
  lic.LicSeq = 0;
  cfg.License[0] = 0xFF; cfg.License[1] = 0xFF; cfg.License[2] = 0xFF; cfg.License[3] = 0xFF;
  cfg.License[4] = 0xFF; cfg.License[5] = 0xFF; cfg.License[6] = 0xFF; cfg.License[7] = 0xFF;
  cfg.License[8] = 0;
  lic.licenseTimer = 999;

  // Profile
  memset(Profile.Station, 0, 50);
  memset(Profile.City, 0, 50);
  memset(Profile.State, 0, 50);
  memset(Profile.Country, 0, 50);

  // TPA6130A2
  tpa6130_init();

  ReadIdEeprom();
  if(cfg.EepromID != 0x55AA || cfg.prg_rev != PRG_REVISION || cfg.model_type != MODELO) {
	  Carrega_Prog_Default();
	  Read_Enviroment();
  }
  else {
	  Read_Profile();
	  ReadConfig();
	  UpdateValores();
  }

  Realtime.Forward = 5.0f;
  Realtime.Reflected = 1.2f;
  Realtime.Temperature = 32.4f;
  Realtime.SWR = 0.0f;
  Realtime.Load_MisMatch = 0.0f;
  Realtime.Return_Loss = 0.0f;
  Realtime.VPA = 20.4f;
  Realtime.IPA = 3.4f;

  Get_UUID();

  // Start Ethernet Stack
  MX_LWIP_Init();
  MX_MBEDTLS_Init();

  // init code HTTPD
  http_server_netconn_init();

  // Se Nao Tem Numero de Serie Token 0000-0000
  if(cfg.SerialNumber[0] == 0xFF && cfg.SerialNumber[1] == 0xFF && cfg.SerialNumber[2] == 0xFF && cfg.SerialNumber[3] == 0xFF &&
     cfg.SerialNumber[4] == 0xFF && cfg.SerialNumber[5] == 0xFF && cfg.SerialNumber[6] == 0xFF && cfg.SerialNumber[7] == 0xFF     ) {
	 //
		cfg.Token[0] = '0'; cfg.Token[1] = '0'; cfg.Token[2] = '0'; cfg.Token[3] = '0';
		cfg.Token[4] = '0'; cfg.Token[5] = '0'; cfg.Token[6] = '0'; cfg.Token[7] = '0';
		cfg.Token[8] = 0;
		cfg.Token[12] = 1;
	}
	else {
		// Token = SN
		cfg.Token[0] = cfg.SerialNumber[0]+'0'; cfg.Token[1] = cfg.SerialNumber[1]+'0'; cfg.Token[2] = cfg.SerialNumber[2]+'0'; cfg.Token[3] = cfg.SerialNumber[3]+'0';
		cfg.Token[4] = cfg.SerialNumber[4]+'0'; cfg.Token[5] = cfg.SerialNumber[5]+'0'; cfg.Token[6] = cfg.SerialNumber[6]+'0'; cfg.Token[7] = cfg.SerialNumber[7]+'0';
		cfg.Token[8] = 0;
		cfg.Token[12] = 1;
	}
  mqtt_init();

  /* init code SNMP */
  if( cfg.EnableSNMP != 0 ) {
  	initialize_snmp();
  }

  /* Infinite loop */
  for(;;)
  {
	  if(HAL_GetTick() - timer_read_rtc > 1000) {
		  timer_read_rtc = HAL_GetTick();
		  // Get the RTC current Time
		  HAL_PWR_EnableBkUpAccess();
		  __HAL_RCC_BKPRAM_CLK_ENABLE();
		  HAL_RTC_GetTime(&hrtc, &gTime, RTC_FORMAT_BIN);
		  // Get the RTC current Date */
		  HAL_RTC_GetDate(&hrtc, &gDate, RTC_FORMAT_BIN);
		  __HAL_RCC_BKPRAM_CLK_DISABLE();
		  HAL_PWR_DisableBkUpAccess();

		  // Calcule UpTime
		  Calculate_UPTime();
	  }

	  // STM32 Temperature
	  MCU_Temperature();

	  // Leitura GPIO BattInput
	  Read_Remote();

	  // RDS
	  RDS_Task();
	  if (HAL_GetTick() - rds_report > 5000) {
		  RDS_PrintStats();
		  rds_report = HAL_GetTick();
	  }

	  // Save Telemetry Data
	  Telemetry_save();

	  // Protecao Watch-Dog
	  HAL_IWDG_Refresh(&hiwdg1);

	  osDelay(10);
  }
  /* USER CODE END StartTaskMain */
}

void StartTaskGUI(void *argument)
{
  /* USER CODE BEGIN StartTaskGUI */
  Evt_InitQueue();
  KeyboardInit(0x01);

	// Init Flash QSPI
  qspi_ret = BSP_QSPI_Init();
  // Mount Flash FATFS
  MX_FATFS_Init();
  Mount_FATFS_QSPI();

  lv_disp_buf_init(&disp_buf, lvgl_buf_1, lvgl_buf_2, LV_HOR_RES_MAX * 16);    // Initialize the display buffer
  lv_init(0);

  // Lvgl File System
  lv_fs_if_init();

  // LVGL Setup
  lv_disp_drv_t disp_drv;               		// Descriptor of a display driver
  lv_disp_drv_init(&disp_drv);          		// Basic initialization
  // SSD1963
  disp_drv.hor_res = 480;               		// Set the horizontal resolution
  disp_drv.ver_res = 128;               		// Set the vertical resolution
  disp_drv.flush_cb = drv_ssd1963_flush_3;		// Set your driver function
  //disp_drv.flush_cb = ssd1963_flush_dma;		// Set your driver function
  //disp_drv.flush_cb = ssd1963_flush_dma_d;		// Set your driver function

  disp_drv.buffer = &disp_buf;          		// Assign the buffer to display
  lv_disp_drv_register(&disp_drv);      		// Finally register the driver

  // Add Log
#if LV_USE_LOG
  lv_log_register_print_cb(my_loglvgl);
#endif

  main_screen_RX();

  /* Infinite loop */
  for(;;)
  {
  		// Eventos da GUI LittleVGL
  		xSemaphoreTake(MutexLVGLHandle, portMAX_DELAY);
  		lv_task_handler();
 		xSemaphoreGive(MutexLVGLHandle);
  		// Eventos  Teclado
  		ButtonEvent();
  		// Dados Uso Memoria LVGL
 		lv_mem_monitor(&mon);

 		osDelay(5);
  }
  /* USER CODE END StartTaskGUI */
}

static void ntp_set_packet(ntp_packet_t *packet) {
    memset(packet, 0, sizeof(ntp_packet_t));

    // LI = 0 (sem aviso), VN = 4 (vers?o 4), Mode = 3 (cliente)
    packet->li_vn_mode = (0 << 6) | (4 << 3) | (3 << 0);

    // Timestamp de transmiss?o (tempo atual aproximado)
    uint32_t current_time = (uint32_t)time(NULL) + NTP_OFFSET;
    packet->trans_ts_sec = __REV(current_time);
}

static time_t ntp_get_time(void) {
    struct netconn *conn = NULL;
    err_t err;
    time_t ntp_time = 0;

    // Criar conex?o UDP
    conn = netconn_new(NETCONN_UDP);
    if (conn == NULL) {
        return 0;
    }

    // Configurar timeout
    netconn_set_recvtimeout(conn, NTP_TIMEOUT);

    // Resolver endere?o do servidor NTP
    ip_addr_t ntp_addr;
    err = netconn_gethostbyname(NTP_SERVER, &ntp_addr);
    if (err != ERR_OK) {
        netconn_close(conn);
        netconn_delete(conn);
        return 0;
    }

    // Conectar ao servidor NTP (opcional para UDP, mas ?til)
    err = netconn_connect(conn, &ntp_addr, NTP_PORT);
    if (err != ERR_OK) {
        netconn_close(conn);
        netconn_delete(conn);
        return 0;
    }

    // Preparar pacote NTP
    ntp_packet_t ntp_request;
    ntp_set_packet(&ntp_request);

    // Enviar requisi??o CORRETAMENTE
    struct netbuf *buf_send = netbuf_new();
    if (buf_send) {
        void *payload = netbuf_alloc(buf_send, sizeof(ntp_packet_t));
        if (payload) {
            memcpy(payload, &ntp_request, sizeof(ntp_packet_t));
            err = netconn_send(conn, buf_send);
            if (err != ERR_OK) {
            }
        }
        netbuf_delete(buf_send);
    }

    // Receber resposta
    struct netbuf *buf_recv;
    err = netconn_recv(conn, &buf_recv);
    if (err == ERR_OK) {
        void *data;
        u16_t len;

        netbuf_data(buf_recv, &data, &len);

        if (len >= sizeof(ntp_packet_t)) {
            ntp_packet_t *response = (ntp_packet_t *)data;

            // Converter timestamp de rede para host
            uint32_t ntp_seconds = __REV(response->trans_ts_sec);

            // Converter de tempo NTP (1900) para Unix (1970)
            ntp_time = (time_t)(ntp_seconds - NTP_OFFSET);

        } else {
        }

        netbuf_delete(buf_recv);
    } else {
    }

    // Fechar e deletar conex?o
    netconn_close(conn);
    netconn_delete(conn);

    return ntp_time;
}

void StartTaskNTP(void *argument)
{
	struct tm *info;

	 /* USER CODE BEGIN StartTaskNTP */
	for(;;)
	{
		time_t current_time = ntp_get_time();

		if (current_time > 0) {
			// Atualizar o rel?gio do sistema
			// (implemente sua fun??o de set_time aqui)
			info = localtime(&current_time);
			sprintf(str_ntp, "NTP: W: %d - D: %02d/%02d/%04d  T: %02d:%02d:%02d\n",
					info->tm_wday, info->tm_mday, info->tm_mon + 1, info->tm_year + 1900,
					info->tm_hour, info->tm_min, info->tm_sec );
			//
			if(cfg.NTP) {
				// Dia-Semana-Dia-Mes-Ano-HH:MM:SS
				gDateAdj.WeekDay = info->tm_wday;
				gDateAdj.Year = (uint8_t)((info->tm_year + 1900)-2000);
				gDateAdj.Month = info->tm_mon + 1;
				gDateAdj.Date = info->tm_mday;

				gTimeAdj.Hours   = info->tm_hour + fuso_offset[cfg.Timezone];
				gTimeAdj.Minutes = info->tm_min;
				gTimeAdj.Seconds = info->tm_sec;

				// Acerta Relogio
				HAL_PWR_EnableBkUpAccess();
				__HAL_RCC_BKPRAM_CLK_ENABLE();
				HAL_RTC_SetTime(&hrtc, &gTimeAdj, RTC_FORMAT_BIN);
				// Get the RTC current Date */
				HAL_RTC_SetDate(&hrtc, &gDateAdj, RTC_FORMAT_BIN);
				__HAL_RCC_BKPRAM_CLK_DISABLE();
				HAL_PWR_DisableBkUpAccess();
			}

			// Sincronizar a cada hora
			vTaskDelay(pdMS_TO_TICKS(3600000));
		} else {
			// Tentar novamente ap?s delay em caso de falha
			vTaskDelay(pdMS_TO_TICKS(NTP_RETRY_DELAY));
		}
	}
}

/* USER CODE BEGIN Application */
void Mount_FATFS_QSPI(void)
{
	  if(retUSER != 0) {
		  // Erro FATFS
		  printf("Erro MX_FATFS_Init !!\n");
	  }
	  else {
		  printf("MX_FATFS_Init OK !!\n");
	  }

	  // Mount FileSystem FLASH QSPI
	  fr = f_mount(&USERFatFS, USERPath, 1);
	  if(fr != FR_OK) {
		  printf("Erro f_mount !!\n");
	  }
	  else {
		  printf("f_mount OK !!\n");
	  }

	  // Check freeSpace space
	  fr = f_getfree("0:", &fre_clust, &pfs);
	  if(fr != FR_OK){
		  printf("Erro f_getfree !!\n");
	  }
	  else {
		  printf("f_getfree OK !!\n");

		  totalSpace = (uint32_t)((pfs->n_fatent - 2) * pfs->csize * 0.5);
		  freeSpace = (uint32_t)(fre_clust * pfs->csize * 0.5);
		  SpaceUsed = totalSpace - freeSpace;
	  }

	  // Test Open config.txt
	  fr = f_open(&USERFile, "/Config.bin", FA_READ);
	  if(fr != FR_OK) {
		  printf("Erro f_open Config.bin !!\n");
	  }
	  else {
		  fr = f_sync(&USERFile);
		  size = f_size(&USERFile);
	      fr = f_read(&USERFile, line , size, &ByteRead);
	      if(fr == FR_OK) {
	    	  for(uint8_t x = 0; x < size-1; x++) {
				  version_flash[x] = line[x+26];
			  }
	      }
	      else {

	      }
	      f_close(&USERFile);
	  }
	  // Test Open File + 8 Caracteres Tela_Main_2025.bin
	  duracao = HAL_GetTick();
	  fr = f_open(&USERFile, "0:/Tela/Tela_Principal.bin/", FA_READ);
	  if(fr != FR_OK) {
		  //logI("STM32H743 FatFs - Tela_Principal.bin Error...Result: %d\n\r", fr);
	  }
	  else {
		duracao = HAL_GetTick() - duracao;
		size = f_size(&USERFile);
		//logI("STM32H743 FatFs - Open File Tela_Principal.bin... Result: %d  Size:%d Duracao: %d\n\r", fr, size, duracao);
		duracao = HAL_GetTick();
		fr = f_read(&USERFile, line , 100, &ByteRead);
		duracao = HAL_GetTick() - duracao;
		if(fr == FR_OK) {
			//logI("STM32H743 FatFs ReadFile...line: %s\n\r", line);
		}
		else {
			//logI("STM32H743 FatFs ReadFile...Error:  Result: %d \n\r", fr);
		}
		f_close(&USERFile);
	}
}

void my_loglvgl(lv_log_level_t level, const char *file, uint32_t line, const char *dsc)
{
}

/* USER CODE END Application */
